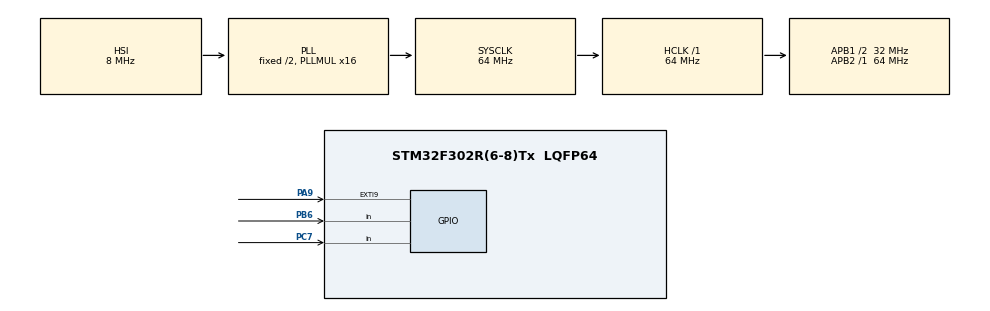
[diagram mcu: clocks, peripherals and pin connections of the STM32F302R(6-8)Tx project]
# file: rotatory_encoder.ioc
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Mcu.Family=STM32F3
Mcu.Name=STM32F302R(6-8)Tx
Mcu.Package=LQFP64
NVIC.EXTI9_5_IRQn=true\:0\:0\:false\:false\:true\:true\:true\:true
NVIC.PriorityGroup=NVIC_PRIORITYGROUP_0
PA13.Mode=Serial_Wire
PA13.Signal=SYS_JTMS-SWDIO
PA14.Mode=Serial_Wire
PA14.Signal=SYS_JTCK-SWCLK
PA9.GPIO_PuPd=GPIO_NOPULL
PA9.Signal=GPXTI9
PB6.Signal=GPIO_Input
PC7.Signal=GPIO_Input
PF0-OSC_IN.Mode=HSE-External-Oscillator
PF0-OSC_IN.Signal=RCC_OSC_IN
PF1-OSC_OUT.Mode=HSE-External-Oscillator
PF1-OSC_OUT.Signal=RCC_OSC_OUT
ProjectManager.HeapSize=0x200
ProjectManager.StackSize=0x400
ProjectManager.TargetToolchain=STM32CubeIDE
RCC.AHBFreq_Value=64000000
RCC.APB1CLKDivider=RCC_HCLK_DIV2
RCC.APB1Freq_Value=32000000
RCC.APB1TimFreq_Value=64000000
RCC.APB2Freq_Value=64000000
RCC.APB2TimFreq_Value=64000000
RCC.CortexFreq_Value=64000000
RCC.HCLKFreq_Value=64000000
RCC.HSE_VALUE=8000000
RCC.HSI_VALUE=8000000
RCC.PLLM=8
RCC.PLLMUL=RCC_PLL_MUL16
RCC.PLLN=336
RCC.PLLP=RCC_PLLP_DIV4
RCC.PLLQ=7
RCC.RCC_PLLsource_Clock_Source_FROM_HSE=RCC_HSE_PREDIV_DIV2
RCC.SYSCLKFreq_VALUE=64000000
RCC.SYSCLKSourceVirtual=RCC_SYSCLKSOURCE_PLLCLK
RCC.USBFreq_Value=64000000
board=NUCLEO-F302R8

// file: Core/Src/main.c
/* USER CODE BEGIN Header */
/**
  ******************************************************************************
  * @file           : main.c
  * @brief          : Main program body
  ******************************************************************************
  * @attention
  *
  * Copyright (c) 2024 STMicroelectronics.
  * All rights reserved.
  *
  * This software is licensed under terms that can be found in the LICENSE file
  * in the root directory of this software component.
  * If no LICENSE file comes with this software, it is provided AS-IS.
  *
  ******************************************************************************
  */
/* USER CODE END Header */
#include "main.h"

void SystemClock_Config(void);
static void MX_GPIO_Init(void);

/* USER CODE BEGIN 0 */
int count=0;
int pin_last=0;
int aval=0;
int flag=0;
int button;

void HAL_GPIO_EXTI_Callback(uint16_t GPIO_Pin)
{
//	HAL_GPIO_TogglePin(GPIOB, GPIO_PIN_13);
//	if(HAL_GPIO_ReadPin(GPIOA, GPIO_PIN_9)==GPIO_PIN_SET)
//	{
	flag++;
	if(flag)
	{
		button=count;
		flag=0;
	}
//	}
//	 if(flag==12)
//			  {
//				  flag=0;
//			  }
}
/* USER CODE END 0 */

int main(void)
{

  /* MCU Configuration--------------------------------------------------------*/

  /* Reset of all peripherals, Initializes the Flash interface and the Systick. */
  HAL_Init();

  /* Configure the system clock */
  SystemClock_Config();

  /* Initialize all configured peripherals */
  MX_GPIO_Init();
  /* USER CODE BEGIN 2 */
pin_last=HAL_GPIO_ReadPin(GPIOB, GPIO_PIN_6);
  /* USER CODE END 2 */

  /* Infinite loop */
  /* USER CODE BEGIN WHILE */
  while (1)
  {
	  aval=HAL_GPIO_ReadPin(GPIOB, GPIO_PIN_6);
	  if(aval!=pin_last)
	  {
		  if(HAL_GPIO_ReadPin(GPIOC	,GPIO_PIN_7)!=aval)
		  {
			  count++;

		  }
		  else
		  {
			  count--;
		  }
	  }
	  if(count>100)
	  {
		  count=100;
	  }
	  if(count<0)
	  {
		  count=0;
	  }
	  pin_last=aval;

//	  if(flag)
//	  {
//		  button=count;
//	  flag=0;
//	  }

//	  if(HAL_GPIO_ReadPin(GPIOA, GPIO_PIN_9)==0)
//	 	  {
//	 		  flag++;
//	 		  while(HAL_GPIO_ReadPin(GPIOA, GPIO_PIN_9)==0);
//	 	  }
    /* USER CODE END WHILE */

  }
}

void SystemClock_Config(void)
{
  RCC_OscInitTypeDef RCC_OscInitStruct = {0};
  RCC_ClkInitTypeDef RCC_ClkInitStruct = {0};

  /** Initializes the RCC Oscillators according to the specified parameters
  * in the RCC_OscInitTypeDef structure.
  */
  RCC_OscInitStruct.OscillatorType = RCC_OSCILLATORTYPE_HSI;
  RCC_OscInitStruct.HSIState = RCC_HSI_ON;
  RCC_OscInitStruct.HSICalibrationValue = RCC_HSICALIBRATION_DEFAULT;
  RCC_OscInitStruct.PLL.PLLState = RCC_PLL_ON;
  RCC_OscInitStruct.PLL.PLLSource = RCC_PLLSOURCE_HSI;
  RCC_OscInitStruct.PLL.PLLMUL = RCC_PLL_MUL16;
  if (HAL_RCC_OscConfig(&RCC_OscInitStruct) != HAL_OK)
  {
    Error_Handler();
  }

  /** Initializes the CPU, AHB and APB buses clocks
  */
  RCC_ClkInitStruct.ClockType = RCC_CLOCKTYPE_HCLK|RCC_CLOCKTYPE_SYSCLK
                              |RCC_CLOCKTYPE_PCLK1|RCC_CLOCKTYPE_PCLK2;
  RCC_ClkInitStruct.SYSCLKSource = RCC_SYSCLKSOURCE_PLLCLK;
  RCC_ClkInitStruct.AHBCLKDivider = RCC_SYSCLK_DIV1;
  RCC_ClkInitStruct.APB1CLKDivider = RCC_HCLK_DIV2;
  RCC_ClkInitStruct.APB2CLKDivider = RCC_HCLK_DIV1;

  if (HAL_RCC_ClockConfig(&RCC_ClkInitStruct, FLASH_LATENCY_2) != HAL_OK)
  {
    Error_Handler();
  }
}

static void MX_GPIO_Init(void)
{
  GPIO_InitTypeDef GPIO_InitStruct = {0};

  /* GPIO Ports Clock Enable */
  __HAL_RCC_GPIOF_CLK_ENABLE();
  __HAL_RCC_GPIOC_CLK_ENABLE();
  __HAL_RCC_GPIOA_CLK_ENABLE();
  __HAL_RCC_GPIOB_CLK_ENABLE();

  /*Configure GPIO pin : PC7 */
  GPIO_InitStruct.Pin = GPIO_PIN_7;
  GPIO_InitStruct.Mode = GPIO_MODE_INPUT;
  GPIO_InitStruct.Pull = GPIO_NOPULL;
  HAL_GPIO_Init(GPIOC, &GPIO_InitStruct);

  /*Configure GPIO pin : PA9 */
  GPIO_InitStruct.Pin = GPIO_PIN_9;
  GPIO_InitStruct.Mode = GPIO_MODE_IT_RISING;
  GPIO_InitStruct.Pull = GPIO_NOPULL;
  HAL_GPIO_Init(GPIOA, &GPIO_InitStruct);

  /*Configure GPIO pin : PB6 */
  GPIO_InitStruct.Pin = GPIO_PIN_6;
  GPIO_InitStruct.Mode = GPIO_MODE_INPUT;
  GPIO_InitStruct.Pull = GPIO_NOPULL;
  HAL_GPIO_Init(GPIOB, &GPIO_InitStruct);

  /* EXTI interrupt init*/
  HAL_NVIC_SetPriority(EXTI9_5_IRQn, 0, 0);
  HAL_NVIC_EnableIRQ(EXTI9_5_IRQn);

}

void Error_Handler(void)
{
  __disable_irq();
  while (1)
  {
  }
}
